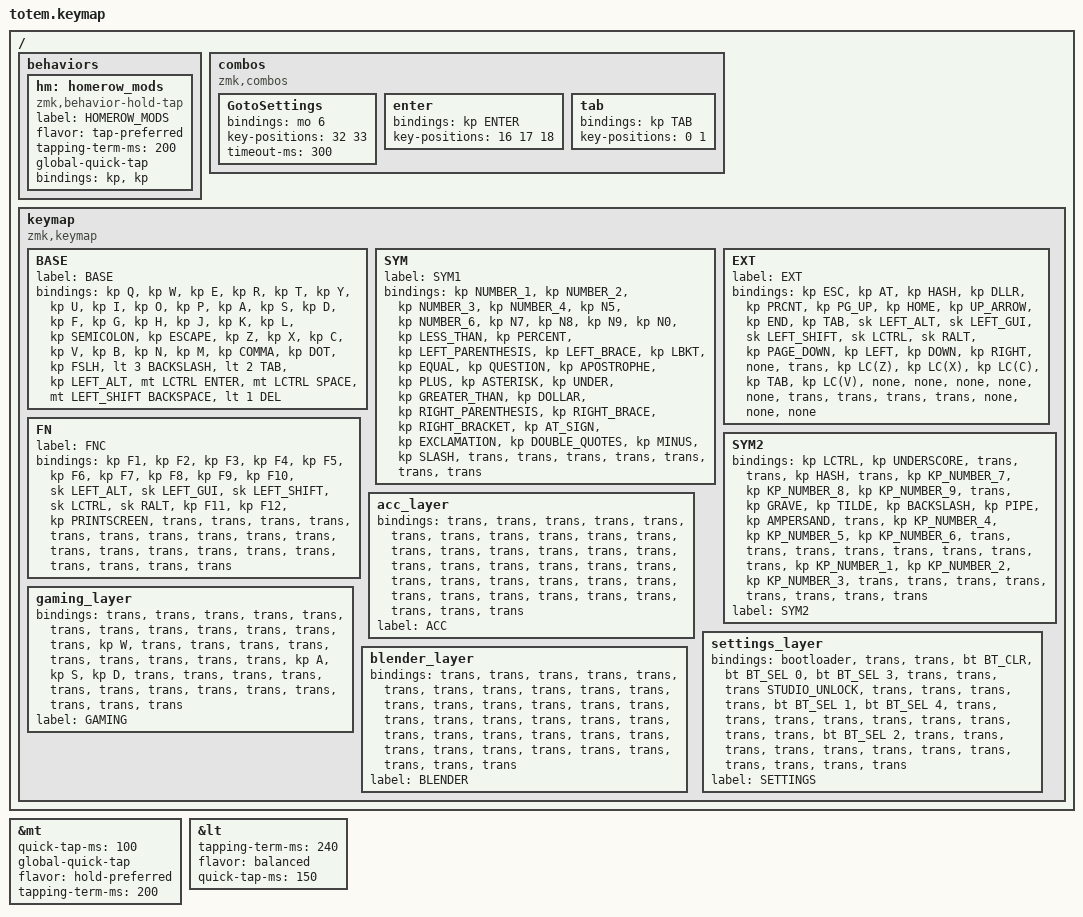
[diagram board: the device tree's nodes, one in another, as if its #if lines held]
//
//                                                        ▀▀▀▀▀     ▀▀▀▀▀          ▀▀█▀▀
//                                                        ▄▀▀▀▄  ▄  ▄▀▀▀▄  ▄  ▄▀▀▀▄  █  ▄▀▀▀▄
//                                                        █   █  █  █   █  █  █   █  █  █   █
//                                                         ▀▀▀   █   ▀▀▀   █   ▀▀▀   ▀   ▀▀▀
//                                                               █      ▄▄▄█▄▄▄    █   █  
//                                                               ▀      █  █  █     █▄█
//                                                             ▀▀▀▀▀    █  █  █      ▀
//                                                                      ▀  ▀  ▀
//
// ▄▄▄▄▄▄▄▄▄▄▄▄▄▄▄▄▄▄▄▄▄▄▄▄▄▄▄▄▄▄▄▄▄▄▄▄▄▄▄▄▄▄▄▄▄▄▄▄▄▄▄▄▄▄▄▄▄▄▄▄▄▄▄▄▄▄▄▄▄▄▄▄▄▄▄▄▄▄▄▄▄▄▄▄▄▄▄▄▄▄▄▄▄▄▄▄▄▄▄▄▄▄▄▄▄▄▄▄▄▄▄▄▄▄▄▄▄▄▄▄▄▄▄▄▄▄▄▄▄▄▄▄▄▄▄▄▄▄▄▄▄▄▄▄▄▄▄▄▄

#include <behaviors.dtsi>
#include <dt-bindings/zmk/bt.h>
#include <dt-bindings/zmk/keys.h>

#ifdef CONFIG_ZMK_STUDIO
#include <dt-bindings/zmk/studio.h>
#define STUDIO_UNLOCK &studio_unlock
#else
#define STUDIO_UNLOCK &none
#endif

#define BASE 0
#define NAV  1
#define SYM  2
#define ADJ  3

&mt {
    quick-tap-ms = <100>;
    global-quick-tap;
    flavor = "hold-preferred";
    tapping-term-ms = <200>;
};

&lt {
    tapping-term-ms = <240>;
    flavor = "balanced";
    quick-tap-ms = <150>;
};

/ {
    behaviors {
        hm: homerow_mods {
            compatible = "zmk,behavior-hold-tap";
            label = "HOMEROW_MODS";
            #binding-cells = <2>;
            flavor = "tap-preferred";
            tapping-term-ms = <200>;
            global-quick-tap;
            bindings = <&kp>, <&kp>;
        };
    };

    combos {
        compatible = "zmk,combos";

        GotoSettings {
            bindings = <&mo 6>;
            key-positions = <32 33>;
            timeout-ms = <300>;
        };

        enter {
            bindings = <&kp ENTER>;
            key-positions = <16 17 18>;
        };

        tab {
            bindings = <&kp TAB>;
            key-positions = <0 1>;
        };
    };

    keymap {
        compatible = "zmk,keymap";

        // ▄▄▄▄▄▄▄▄▄▄▄▄▄▄▄▄▄▄▄▄▄▄▄▄▄▄▄▄▄▄▄▄▄▄▄▄▄▄▄▄▄▄▄▄▄▄▄▄▄▄▄▄▄▄▄▄▄▄▄▄▄▄▄▄▄▄▄▄▄▄▄▄▄▄▄▄▄▄▄▄▄▄▄▄▄▄▄▄▄▄▄▄▄▄▄▄▄▄▄▄▄▄▄▄▄▄▄▄▄▄▄▄▄▄▄▄▄▄▄▄▄▄▄▄▄▄▄▄▄▄▄▄▄▄▄▄▄▄▄▄▄▄▄▄▄▄▄▄▄

        BASE {
            // ┏━━━━━━━━━━━━━━━━━━━━━━━━━━━━━━━━━━━━━━━┓

            label = "BASE";

            // ┗━━━━━━━━━━━━━━━━━━━━━━━━━━━━━━━━━━━━━━━┛
            //             ┏━━━━━━━━━━━┳━━━━━━━━━━━┳━━━━━━━━━━━┳━━━━━━━━━━━┳━━━━━━━━━━━┓   ┏━━━━━━━━━━━┳━━━━━━━━━━━┳━━━━━━━━━━━┳━━━━━━━━━━━┳━━━━━━━━━━━┓
            //             ┃     Q     ┃     W     ┃     E     ┃     R     ┃     T     ┃   ┃     Y     ┃     U     ┃     I     ┃     O     ┃     P     ┃
            //             ┣━━━━━━━━━━━╋━━━━━━━━━━━╋━━━━━━━━━━━╋━━━━━━━━━━━╋━━━━━━━━━━━┫   ┣━━━━━━━━━━━╋━━━━━━━━━━━╋━━━━━━━━━━━╋━━━━━━━━━━━╋━━━━━━━━━━━┫
            //             ┃     A     ┃     S     ┃     D     ┃     F     ┃     G     ┃   ┃     H     ┃     J     ┃     K     ┃     L     ┃     ;     ┃
            // ┏━━━━━━━━━━━╋━━━━━━━━━━━╋━━━━━━━━━━━╋━━━━━━━━━━━╋━━━━━━━━━━━╋━━━━━━━━━━━┫   ┣━━━━━━━━━━━╋━━━━━━━━━━━╋━━━━━━━━━━━╋━━━━━━━━━━━╋━━━━━━━━━━━╋━━━━━━━━━━━┓
            // ┃     Q     ┃     Z     ┃     X     ┃     C     ┃     V     ┃     B     ┃   ┃     N     ┃     M     ┃     ,     ┃     .     ┃     /     ┃     \     ┃
            // ┗━━━━━━━━━━━┻━━━━━━━━━━━┻━━━━━━━━━━━╋━━━━━━━━━━━╋━━━━━━━━━━━╋━━━━━━━━━━━┫   ┣━━━━━━━━━━━╋━━━━━━━━━━━╋━━━━━━━━━━━╋━━━━━━━━━━━┻━━━━━━━━━━━┻━━━━━━━━━━━┛
            //                                     ┃    DEL    ┃    TAB    ┃    SPC    ┃   ┃   ENTER   ┃           ┃   BSPC    ┃
            //                                     ┗━━━━━━━━━━━┻━━━━━━━━━━━┻━━━━━━━━━━━┛   ┗━━━━━━━━━━━┻━━━━━━━━━━━┻━━━━━━━━━━━┛

            bindings = <
            &kp Q  &kp W  &kp E      &kp R         &kp T              &kp Y            &kp U                     &kp I      &kp O    &kp P
            &kp A  &kp S  &kp D      &kp F         &kp G              &kp H            &kp J                     &kp K      &kp L    &kp SEMICOLON
&kp ESCAPE  &kp Z  &kp X  &kp C      &kp V         &kp B              &kp N            &kp M                     &kp COMMA  &kp DOT  &kp FSLH       &lt 3 BACKSLASH
                          &lt 2 TAB  &kp LEFT_ALT  &mt LCTRL ENTER    &mt LCTRL SPACE  &mt LEFT_SHIFT BACKSPACE  &lt 1 DEL
            >;
        };

        // ▄▄▄▄▄▄▄▄▄▄▄▄▄▄▄▄▄▄▄▄▄▄▄▄▄▄▄▄▄▄▄▄▄▄▄▄▄▄▄▄▄▄▄▄▄▄▄▄▄▄▄▄▄▄▄▄▄▄▄▄▄▄▄▄▄▄▄▄▄▄▄▄▄▄▄▄▄▄▄▄▄▄▄▄▄▄▄▄▄▄▄▄▄▄▄▄▄▄▄▄▄▄▄▄▄▄▄▄▄▄▄▄▄▄▄▄▄▄▄▄▄▄▄▄▄▄▄▄▄▄▄▄▄▄▄▄▄▄▄▄▄▄▄▄▄▄▄▄▄

        SYM {
            // ┏━━━━━━━━━━━━━━━━━━━━━━━━━━━━━━━━━━━━━━━┓

            label = "SYM1";

            // ┗━━━━━━━━━━━━━━━━━━━━━━━━━━━━━━━━━━━━━━━┛
            //             ┏━━━━━━━━━━━┳━━━━━━━━━━━┳━━━━━━━━━━━┳━━━━━━━━━━━┳━━━━━━━━━━━┓   ┏━━━━━━━━━━━┳━━━━━━━━━━━┳━━━━━━━━━━━┳━━━━━━━━━━━┳━━━━━━━━━━━┓
            //             ┃           ┃           ┃     UP    ┃           ┃     {     ┃   ┃     }     ┃     7     ┃     8     ┃     9     ┃     +     ┃
            //             ┣━━━━━━━━━━━╋━━━━━━━━━━━╋━━━━━━━━━━━╋━━━━━━━━━━━╋━━━━━━━━━━━┫   ┣━━━━━━━━━━━╋━━━━━━━━━━━╋━━━━━━━━━━━╋━━━━━━━━━━━╋━━━━━━━━━━━┫
            //             ┃   SHIFT   ┃   LEFT    ┃    DOWN   ┃   RIGHT   ┃     [     ┃   ┃     ]     ┃     4     ┃     5     ┃     6     ┃     -     ┃
            // ┏━━━━━━━━━━━╋━━━━━━━━━━━╋━━━━━━━━━━━╋━━━━━━━━━━━╋━━━━━━━━━━━╋━━━━━━━━━━━┫   ┣━━━━━━━━━━━╋━━━━━━━━━━━╋━━━━━━━━━━━╋━━━━━━━━━━━╋━━━━━━━━━━━╋━━━━━━━━━━━┓
            // ┃           ┃           ┃   P UP    ┃  C LOCK   ┃  P DOWN   ┃     (     ┃   ┃     )     ┃     1     ┃     2     ┃     3     ┃     *     ┃           ┃
            // ┗━━━━━━━━━━━┻━━━━━━━━━━━┻━━━━━━━━━━━╋━━━━━━━━━━━╋━━━━━━━━━━━╋━━━━━━━━━━━┫   ┣━━━━━━━━━━━╋━━━━━━━━━━━╋━━━━━━━━━━━╋━━━━━━━━━━━┻━━━━━━━━━━━┻━━━━━━━━━━━┛
            //                                     ┃           ┃    TAB    ┃    SPC    ┃   ┃    DEL    ┃     0     ┃           ┃
            //                                     ┗━━━━━━━━━━━┻━━━━━━━━━━━┻━━━━━━━━━━━┛   ┗━━━━━━━━━━━┻━━━━━━━━━━━┻━━━━━━━━━━━┛

            bindings = <
           &kp NUMBER_1      &kp NUMBER_2  &kp NUMBER_3           &kp NUMBER_4     &kp N5               &kp NUMBER_6  &kp N7           &kp N8             &kp N9     &kp N0
           &kp LESS_THAN     &kp PERCENT   &kp LEFT_PARENTHESIS   &kp LEFT_BRACE   &kp LBKT             &kp EQUAL     &kp QUESTION     &kp APOSTROPHE     &kp PLUS   &kp ASTERISK
&kp UNDER  &kp GREATER_THAN  &kp DOLLAR    &kp RIGHT_PARENTHESIS  &kp RIGHT_BRACE  &kp RIGHT_BRACKET    &kp AT_SIGN   &kp EXCLAMATION  &kp DOUBLE_QUOTES  &kp MINUS  &kp SLASH     &trans
                                           &trans                 &trans           &trans               &trans        &trans           &trans
            >;
        };

        // ▄▄▄▄▄▄▄▄▄▄▄▄▄▄▄▄▄▄▄▄▄▄▄▄▄▄▄▄▄▄▄▄▄▄▄▄▄▄▄▄▄▄▄▄▄▄▄▄▄▄▄▄▄▄▄▄▄▄▄▄▄▄▄▄▄▄▄▄▄▄▄▄▄▄▄▄▄▄▄▄▄▄▄▄▄▄▄▄▄▄▄▄▄▄▄▄▄▄▄▄▄▄▄▄▄▄▄▄▄▄▄▄▄▄▄▄▄▄▄▄▄▄▄▄▄▄▄▄▄▄▄▄▄▄▄▄▄▄▄▄▄▄▄▄▄▄▄▄▄

        EXT {
            // ┏━━━━━━━━━━━━━━━━━━━━━━━━━━━━━━━━━━━━━━━┓

            label = "EXT";

            // ┗━━━━━━━━━━━━━━━━━━━━━━━━━━━━━━━━━━━━━━━┛
            //             ┏━━━━━━━━━━━┳━━━━━━━━━━━┳━━━━━━━━━━━┳━━━━━━━━━━━┳━━━━━━━━━━━┓   ┏━━━━━━━━━━━┳━━━━━━━━━━━┳━━━━━━━━━━━┳━━━━━━━━━━━┳━━━━━━━━━━━┓
            //             ┃     !     ┃     @     ┃     #     ┃     $     ┃     %     ┃   ┃     ˆ     ┃     &     ┃     Ü     ┃     '     ┃     "     ┃
            //             ┣━━━━━━━━━━━╋━━━━━━━━━━━╋━━━━━━━━━━━╋━━━━━━━━━━━╋━━━━━━━━━━━┫   ┣━━━━━━━━━━━╋━━━━━━━━━━━╋━━━━━━━━━━━╋━━━━━━━━━━━╋━━━━━━━━━━━┫
            //             ┃     Ä     ┃           ┃    SZ     ┃           ┃           ┃   ┃   MUTE    ┃   YEN     ┃   EURO    ┃  POUND    ┃     Ö     ┃
            // ┏━━━━━━━━━━━╋━━━━━━━━━━━╋━━━━━━━━━━━╋━━━━━━━━━━━╋━━━━━━━━━━━╋━━━━━━━━━━━┫   ┣━━━━━━━━━━━╋━━━━━━━━━━━╋━━━━━━━━━━━╋━━━━━━━━━━━╋━━━━━━━━━━━╋━━━━━━━━━━━┓
            // ┃           ┃  EMAIL1   ┃  EMAIL2   ┃           ┃           ┃           ┃   ┃   VOL-    ┃   VOL+    ┃   LAST    ┃   NEXT    ┃     \     ┃           ┃
            // ┗━━━━━━━━━━━┻━━━━━━━━━━━┻━━━━━━━━━━━╋━━━━━━━━━━━╋━━━━━━━━━━━╋━━━━━━━━━━━┫   ┣━━━━━━━━━━━╋━━━━━━━━━━━╋━━━━━━━━━━━╋━━━━━━━━━━━┻━━━━━━━━━━━┻━━━━━━━━━━━┛
            //                                     ┃           ┃    GIF    ┃    ADJ    ┃   ┃           ┃           ┃           ┃
            //                                     ┗━━━━━━━━━━━┻━━━━━━━━━━━┻━━━━━━━━━━━┛   ┗━━━━━━━━━━━┻━━━━━━━━━━━┻━━━━━━━━━━━┛

            bindings = <
        &kp ESC       &kp AT        &kp HASH        &kp DLLR   &kp PRCNT    &kp PG_UP      &kp HOME  &kp UP_ARROW  &kp END    &kp TAB
        &sk LEFT_ALT  &sk LEFT_GUI  &sk LEFT_SHIFT  &sk LCTRL  &sk RALT     &kp PAGE_DOWN  &kp LEFT  &kp DOWN      &kp RIGHT  &none
&trans  &kp LC(Z)     &kp LC(X)     &kp LC(C)       &kp TAB    &kp LC(V)    &none          &none     &none         &none      &none    &trans
                                    &trans          &trans     &trans       &none          &none     &none
            >;
        };

        // ▄▄▄▄▄▄▄▄▄▄▄▄▄▄▄▄▄▄▄▄▄▄▄▄▄▄▄▄▄▄▄▄▄▄▄▄▄▄▄▄▄▄▄▄▄▄▄▄▄▄▄▄▄▄▄▄▄▄▄▄▄▄▄▄▄▄▄▄▄▄▄▄▄▄▄▄▄▄▄▄▄▄▄▄▄▄▄▄▄▄▄▄▄▄▄▄▄▄▄▄▄▄▄▄▄▄▄▄▄▄▄▄▄▄▄▄▄▄▄▄▄▄▄▄▄▄▄▄▄▄▄▄▄▄▄▄▄▄▄▄▄▄▄▄▄▄▄▄▄

        FN {
            // ┏━━━━━━━━━━━━━━━━━━━━━━━━━━━━━━━━━━━━━━━┓

            label = "FNC";

            // ┗━━━━━━━━━━━━━━━━━━━━━━━━━━━━━━━━━━━━━━━┛
            //             ┏━━━━━━━━━━━┳━━━━━━━━━━━┳━━━━━━━━━━━┳━━━━━━━━━━━┳━━━━━━━━━━━┓   ┏━━━━━━━━━━━┳━━━━━━━━━━━┳━━━━━━━━━━━┳━━━━━━━━━━━┳━━━━━━━━━━━┓
            //             ┃   RESET   ┃ BT CLEAR  ┃  OUT TOG  ┃           ┃           ┃   ┃           ┃    F7     ┃    F8     ┃    F9     ┃    F12    ┃
            //             ┣━━━━━━━━━━━╋━━━━━━━━━━━╋━━━━━━━━━━━╋━━━━━━━━━━━╋━━━━━━━━━━━┫   ┣━━━━━━━━━━━╋━━━━━━━━━━━╋━━━━━━━━━━━╋━━━━━━━━━━━╋━━━━━━━━━━━┫
            //             ┃ BOOTLOAD  ┃ BT NEXT   ┃           ┃           ┃           ┃   ┃           ┃    F4     ┃    F5     ┃    F6     ┃    F11    ┃
            // ┏━━━━━━━━━━━╋━━━━━━━━━━━╋━━━━━━━━━━━╋━━━━━━━━━━━╋━━━━━━━━━━━╋━━━━━━━━━━━┫   ┣━━━━━━━━━━━╋━━━━━━━━━━━╋━━━━━━━━━━━╋━━━━━━━━━━━╋━━━━━━━━━━━╋━━━━━━━━━━━┓
            // ┃           ┃           ┃ BT PREV   ┃           ┃           ┃           ┃   ┃           ┃    F1     ┃    F2     ┃    F3     ┃    F10    ┃           ┃
            // ┗━━━━━━━━━━━┻━━━━━━━━━━━┻━━━━━━━━━━━╋━━━━━━━━━━━╋━━━━━━━━━━━╋━━━━━━━━━━━┫   ┣━━━━━━━━━━━╋━━━━━━━━━━━╋━━━━━━━━━━━╋━━━━━━━━━━━┻━━━━━━━━━━━┻━━━━━━━━━━━┛
            //                                     ┃           ┃           ┃           ┃   ┃           ┃           ┃           ┃
            //                                     ┗━━━━━━━━━━━┻━━━━━━━━━━━┻━━━━━━━━━━━┛   ┗━━━━━━━━━━━┻━━━━━━━━━━━┻━━━━━━━━━━━┛

            bindings = <
        &kp F1        &kp F2        &kp F3          &kp F4     &kp F5      &kp F6   &kp F7   &kp F8           &kp F9  &kp F10
        &sk LEFT_ALT  &sk LEFT_GUI  &sk LEFT_SHIFT  &sk LCTRL  &sk RALT    &kp F11  &kp F12  &kp PRINTSCREEN  &trans  &trans
&trans  &trans        &trans        &trans          &trans     &trans      &trans   &trans   &trans           &trans  &trans   &trans
                                    &trans          &trans     &trans      &trans   &trans   &trans
            >;
        };

        SYM2 {
            bindings = <
        &kp LCTRL  &kp UNDERSCORE  &trans         &trans    &kp HASH         &trans  &kp KP_NUMBER_7  &kp KP_NUMBER_8  &kp KP_NUMBER_9  &trans
        &kp GRAVE  &kp TILDE       &kp BACKSLASH  &kp PIPE  &kp AMPERSAND    &trans  &kp KP_NUMBER_4  &kp KP_NUMBER_5  &kp KP_NUMBER_6  &trans
&trans  &trans     &trans          &trans         &trans    &trans           &trans  &kp KP_NUMBER_1  &kp KP_NUMBER_2  &kp KP_NUMBER_3  &trans  &trans
                                   &trans         &trans    &trans           &trans  &trans           &trans
            >;

            label = "SYM2";
        };

        acc_layer {
            bindings = <
        &trans  &trans  &trans  &trans  &trans    &trans  &trans  &trans  &trans  &trans
        &trans  &trans  &trans  &trans  &trans    &trans  &trans  &trans  &trans  &trans
&trans  &trans  &trans  &trans  &trans  &trans    &trans  &trans  &trans  &trans  &trans  &trans
                        &trans  &trans  &trans    &trans  &trans  &trans
            >;

            label = "ACC";
        };

        settings_layer {
            bindings = <
        &bootloader    &trans  &trans  &bt BT_CLR  &bt BT_SEL 0    &bt BT_SEL 3  &trans  &trans  &trans  STUDIO_UNLOCK
        &trans         &trans  &trans  &trans      &bt BT_SEL 1    &bt BT_SEL 4  &trans  &trans  &trans  &trans
&trans  &trans         &trans  &trans  &trans      &bt BT_SEL 2    &trans        &trans  &trans  &trans  &trans          &trans
                               &trans  &trans      &trans          &trans        &trans  &trans
            >;

            label = "SETTINGS";
        };

        gaming_layer {
            bindings = <
        &trans  &trans  &trans  &trans  &trans    &trans  &trans  &trans  &trans  &trans
        &trans  &trans  &kp W   &trans  &trans    &trans  &trans  &trans  &trans  &trans
&trans  &trans  &kp A   &kp S   &kp D   &trans    &trans  &trans  &trans  &trans  &trans  &trans
                        &trans  &trans  &trans    &trans  &trans  &trans
            >;

            label = "GAMING";
        };

        blender_layer {
            bindings = <
        &trans  &trans  &trans  &trans  &trans    &trans  &trans  &trans  &trans  &trans
        &trans  &trans  &trans  &trans  &trans    &trans  &trans  &trans  &trans  &trans
&trans  &trans  &trans  &trans  &trans  &trans    &trans  &trans  &trans  &trans  &trans  &trans
                        &trans  &trans  &trans    &trans  &trans  &trans
            >;

            label = "BLENDER";
        };
    };
};
